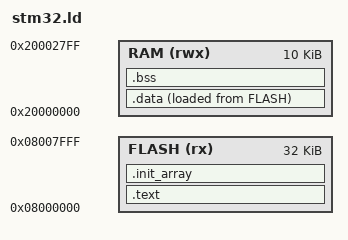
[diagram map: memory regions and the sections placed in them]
ENTRY(Reset_Handler)

MEMORY {
    FLASH (rx)  : ORIGIN = 0x08000000, LENGTH = 32K
    RAM   (rwx) : ORIGIN = 0x20000000, LENGTH = 10K
}

SECTIONS {
    .text : {
        KEEP(*(.isr_vector))
        *(.text*)
        *(.rodata*)
    } > FLASH

    INCLUDE gcov_embedded_lib/ld/gcov_linker.ld.inc

    .init_array : {
        __init_array_start = .;
        KEEP(*(.init_array*))
        __init_array_end = .;
    } > FLASH

    .data : {
        _sdata = .;
        *(.data*)
        _edata = .;
    } > RAM AT > FLASH

    _sidata = LOADADDR(.data);

    .bss : {
        _sbss = .;
        *(.bss*)
        *(COMMON)
        _ebss = .;
    } > RAM

    _estack = ORIGIN(RAM) + LENGTH(RAM);
}
